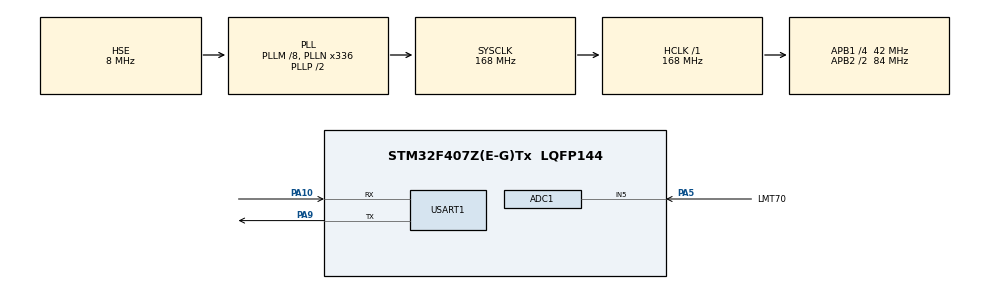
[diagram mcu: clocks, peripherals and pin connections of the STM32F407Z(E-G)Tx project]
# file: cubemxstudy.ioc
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ADC1.Channel-0\#ChannelRegularConversion=ADC_CHANNEL_5
ADC1.NbrOfConversionFlag=1
ADC1.Rank-0\#ChannelRegularConversion=1
ADC1.SamplingTime-0\#ChannelRegularConversion=ADC_SAMPLETIME_56CYCLES
ADC1.master=1
Mcu.Family=STM32F4
Mcu.Name=STM32F407Z(E-G)Tx
Mcu.Package=LQFP144
NVIC.PriorityGroup=NVIC_PRIORITYGROUP_4
NVIC.USART1_IRQn=true\:0\:0\:false\:false\:true\:true\:true\:true
PA10.Mode=Asynchronous
PA10.Signal=USART1_RX
PA13.Mode=Serial_Wire
PA13.Signal=SYS_JTMS-SWDIO
PA14.Mode=Serial_Wire
PA14.Signal=SYS_JTCK-SWCLK
PA5.GPIO_Label=LMT70
PA5.Signal=ADCx_IN5
PA9.Mode=Asynchronous
PA9.Signal=USART1_TX
PC14-OSC32_IN.Mode=LSE-External-Oscillator
PC14-OSC32_IN.Signal=RCC_OSC32_IN
PC15-OSC32_OUT.Mode=LSE-External-Oscillator
PC15-OSC32_OUT.Signal=RCC_OSC32_OUT
PH0-OSC_IN.Mode=HSE-External-Oscillator
PH0-OSC_IN.Signal=RCC_OSC_IN
PH1-OSC_OUT.Mode=HSE-External-Oscillator
PH1-OSC_OUT.Signal=RCC_OSC_OUT
ProjectManager.HeapSize=0x200
ProjectManager.StackSize=0x400
ProjectManager.TargetToolchain=STM32CubeIDE
RCC.48MHZClocksFreq_Value=84000000
RCC.AHBFreq_Value=168000000
RCC.APB1CLKDivider=RCC_HCLK_DIV4
RCC.APB1Freq_Value=42000000
RCC.APB1TimFreq_Value=84000000
RCC.APB2CLKDivider=RCC_HCLK_DIV2
RCC.APB2Freq_Value=84000000
RCC.APB2TimFreq_Value=168000000
RCC.CortexFreq_Value=168000000
RCC.HCLKFreq_Value=168000000
RCC.HSE_VALUE=8000000
RCC.HSI_VALUE=16000000
RCC.PLLM=8
RCC.PLLN=336
RCC.PLLSourceVirtual=RCC_PLLSOURCE_HSE
RCC.SYSCLKFreq_VALUE=168000000
RCC.SYSCLKSource=RCC_SYSCLKSOURCE_PLLCLK
RCC.VCOOutputFreq_Value=336000000
SH.ADCx_IN5.0=ADC1_IN5,IN5
STMicroelectronics.X-CUBE-ALGOBUILD.1.3.0.LibraryCcDSPOoLibraryJjDSPOoLibrary=true
USART1.VirtualMode=VM_ASYNC
VP_STMicroelectronics.X-CUBE-ALGOBUILD_VS_DSPOoLibraryJjLibrary_1.3.0_1.3.0.Mode=DSPOoLibraryJjLibrary
board=custom

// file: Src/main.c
/* USER CODE BEGIN Header */
/**
  ******************************************************************************
  * @file           : main.c
  * @brief          : Main program body
  ******************************************************************************
  * @attention
  *
  * Copyright (c) 2023 STMicroelectronics.
  * All rights reserved.
  *
  * This software is licensed under terms that can be found in the LICENSE file
  * in the root directory of this software component.
  * If no LICENSE file comes with this software, it is provided AS-IS.
  *
  ******************************************************************************
  */
/* USER CODE END Header */
#include "main.h"

/* USER CODE BEGIN Includes */
#include "retarget.h"
#include "adc.h"
#include "LMT70.h"
/* USER CODE END Includes */

ADC_HandleTypeDef hadc1;

UART_HandleTypeDef huart1;

void SystemClock_Config(void);
static void MX_GPIO_Init(void);
static void MX_USART1_UART_Init(void);
static void MX_ADC1_Init(void);

int main(void)
{
  /* USER CODE BEGIN 1 */
    /*全局变量*/
    //ADC变量
    uint16_t ADC_value;//ADC采集值
    double ADC_voltage;//ADC电压值
    double LMT70_temp;//LMT70温度值
  /* USER CODE END 1 */

  /* MCU Configuration--------------------------------------------------------*/

  /* Reset of all peripherals, Initializes the Flash interface and the Systick. */
  HAL_Init();

  /* Configure the system clock */
  SystemClock_Config();

  /* Initialize all configured peripherals */
  MX_GPIO_Init();
  MX_USART1_UART_Init();
  MX_ADC1_Init();
  /* USER CODE BEGIN 2 */
    //注册重定向串口号
    RetargetInit(&huart1);
  /* USER CODE END 2 */

  /* Infinite loop */
  /* USER CODE BEGIN WHILE */
    while (1) {
        ADC_value = Get_Adc(&hadc1);
        ADC_voltage = ADC2Voltage(ADC_value);
        LMT70_temp = LMT70Voltage2Temperature(ADC_voltage);
        printf("ADC_value = %04d \r\n", ADC_value);
        printf("ADC_voltage = %0.1fmv \r\n", ADC_voltage);
        printf("LMT70_temp = %0.2f℃ \r\n", LMT70_temp);
        printf("\r\n");
        HAL_Delay(500);
    /* USER CODE END WHILE */

    }
}

void SystemClock_Config(void)
{
  RCC_OscInitTypeDef RCC_OscInitStruct = {0};
  RCC_ClkInitTypeDef RCC_ClkInitStruct = {0};

  /** Configure the main internal regulator output voltage
  */
  __HAL_RCC_PWR_CLK_ENABLE();
  __HAL_PWR_VOLTAGESCALING_CONFIG(PWR_REGULATOR_VOLTAGE_SCALE1);

  /** Initializes the RCC Oscillators according to the specified parameters
  * in the RCC_OscInitTypeDef structure.
  */
  RCC_OscInitStruct.OscillatorType = RCC_OSCILLATORTYPE_HSE;
  RCC_OscInitStruct.HSEState = RCC_HSE_ON;
  RCC_OscInitStruct.PLL.PLLState = RCC_PLL_ON;
  RCC_OscInitStruct.PLL.PLLSource = RCC_PLLSOURCE_HSE;
  RCC_OscInitStruct.PLL.PLLM = 8;
  RCC_OscInitStruct.PLL.PLLN = 336;
  RCC_OscInitStruct.PLL.PLLP = RCC_PLLP_DIV2;
  RCC_OscInitStruct.PLL.PLLQ = 4;
  if (HAL_RCC_OscConfig(&RCC_OscInitStruct) != HAL_OK)
  {
    Error_Handler();
  }

  /** Initializes the CPU, AHB and APB buses clocks
  */
  RCC_ClkInitStruct.ClockType = RCC_CLOCKTYPE_HCLK|RCC_CLOCKTYPE_SYSCLK
                              |RCC_CLOCKTYPE_PCLK1|RCC_CLOCKTYPE_PCLK2;
  RCC_ClkInitStruct.SYSCLKSource = RCC_SYSCLKSOURCE_PLLCLK;
  RCC_ClkInitStruct.AHBCLKDivider = RCC_SYSCLK_DIV1;
  RCC_ClkInitStruct.APB1CLKDivider = RCC_HCLK_DIV4;
  RCC_ClkInitStruct.APB2CLKDivider = RCC_HCLK_DIV2;

  if (HAL_RCC_ClockConfig(&RCC_ClkInitStruct, FLASH_LATENCY_5) != HAL_OK)
  {
    Error_Handler();
  }
}

static void MX_ADC1_Init(void)
{

  ADC_ChannelConfTypeDef sConfig = {0};

  /** Configure the global features of the ADC (Clock, Resolution, Data Alignment and number of conversion)
  */
  hadc1.Instance = ADC1;
  hadc1.Init.ClockPrescaler = ADC_CLOCK_SYNC_PCLK_DIV4;
  hadc1.Init.Resolution = ADC_RESOLUTION_12B;
  hadc1.Init.ScanConvMode = DISABLE;
  hadc1.Init.ContinuousConvMode = DISABLE;
  hadc1.Init.DiscontinuousConvMode = DISABLE;
  hadc1.Init.ExternalTrigConvEdge = ADC_EXTERNALTRIGCONVEDGE_NONE;
  hadc1.Init.ExternalTrigConv = ADC_SOFTWARE_START;
  hadc1.Init.DataAlign = ADC_DATAALIGN_RIGHT;
  hadc1.Init.NbrOfConversion = 1;
  hadc1.Init.DMAContinuousRequests = DISABLE;
  hadc1.Init.EOCSelection = ADC_EOC_SINGLE_CONV;
  if (HAL_ADC_Init(&hadc1) != HAL_OK)
  {
    Error_Handler();
  }

  /** Configure for the selected ADC regular channel its corresponding rank in the sequencer and its sample time.
  */
  sConfig.Channel = ADC_CHANNEL_5;
  sConfig.Rank = 1;
  sConfig.SamplingTime = ADC_SAMPLETIME_56CYCLES;
  if (HAL_ADC_ConfigChannel(&hadc1, &sConfig) != HAL_OK)
  {
    Error_Handler();
  }

}

static void MX_USART1_UART_Init(void)
{

  huart1.Instance = USART1;
  huart1.Init.BaudRate = 115200;
  huart1.Init.WordLength = UART_WORDLENGTH_8B;
  huart1.Init.StopBits = UART_STOPBITS_1;
  huart1.Init.Parity = UART_PARITY_NONE;
  huart1.Init.Mode = UART_MODE_TX_RX;
  huart1.Init.HwFlowCtl = UART_HWCONTROL_NONE;
  huart1.Init.OverSampling = UART_OVERSAMPLING_16;
  if (HAL_UART_Init(&huart1) != HAL_OK)
  {
    Error_Handler();
  }

}

static void MX_GPIO_Init(void)
{

  /* GPIO Ports Clock Enable */
  __HAL_RCC_GPIOC_CLK_ENABLE();
  __HAL_RCC_GPIOH_CLK_ENABLE();
  __HAL_RCC_GPIOA_CLK_ENABLE();

}

void Error_Handler(void)
{
    __disable_irq();
    while (1) {
    }
}
